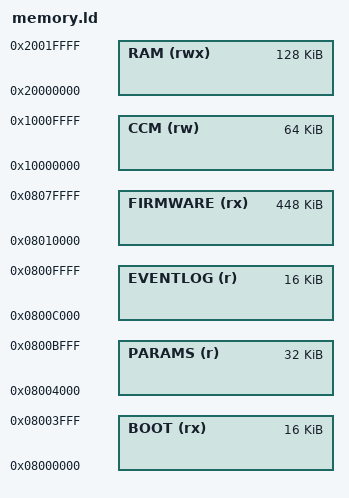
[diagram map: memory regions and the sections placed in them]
/* Generated by tools/generators/generate_board.py from boards/c50c-v1_1/board.toml. Do not edit. */
/* Region sizes are the size budgets the linker enforces (ADR-0017, ADR-0020). */
MEMORY
{
    BOOT     (rx)  : ORIGIN = 0x08000000, LENGTH = 16K
    PARAMS   (r)   : ORIGIN = 0x08004000, LENGTH = 32K
    EVENTLOG (r)   : ORIGIN = 0x0800C000, LENGTH = 16K
    FIRMWARE (rx)  : ORIGIN = 0x08010000, LENGTH = 448K
    CCM      (rw)  : ORIGIN = 0x10000000, LENGTH = 64K
    RAM      (rwx) : ORIGIN = 0x20000000, LENGTH = 128K
}

__vk_flash_boot_start = ORIGIN(BOOT);
__vk_flash_boot_end = ORIGIN(BOOT) + LENGTH(BOOT);
__vk_flash_params_start = ORIGIN(PARAMS);
__vk_flash_params_end = ORIGIN(PARAMS) + LENGTH(PARAMS);
__vk_flash_eventlog_start = ORIGIN(EVENTLOG);
__vk_flash_eventlog_end = ORIGIN(EVENTLOG) + LENGTH(EVENTLOG);
__vk_flash_firmware_start = ORIGIN(FIRMWARE);
__vk_flash_firmware_end = ORIGIN(FIRMWARE) + LENGTH(FIRMWARE);
